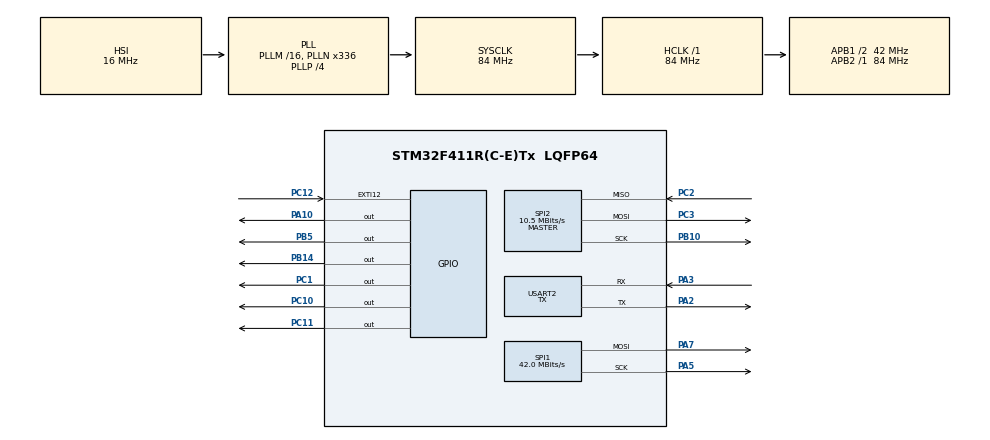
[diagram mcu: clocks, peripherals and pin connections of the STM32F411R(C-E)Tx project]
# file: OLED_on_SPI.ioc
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FREERTOS.Tasks01=defaultTask,8,128,StartDefaultTask,Default,NULL,Dynamic,NULL,NULL
FREERTOS.configCHECK_FOR_STACK_OVERFLOW=1
FREERTOS.configENABLE_FPU=1
FREERTOS.configTIMER_TASK_PRIORITY=12
FREERTOS.configTOTAL_HEAP_SIZE=30360
FREERTOS.configUSE_NEWLIB_REENTRANT=1
FREERTOS.configUSE_OS2_TIMER=0
MBEDTLS.MBEDTLS_DEBUG_C=1
MBEDTLS.MBEDTLS_HAVE_TIME=0
MBEDTLS.MBEDTLS_KEY_EXCHANGE_ECDHE_ECDSA_ENABLED=0
MBEDTLS.MBEDTLS_KEY_EXCHANGE_ECDHE_RSA_ENABLED=1
MBEDTLS.MBEDTLS_KEY_EXCHANGE_ECDH_RSA_ENABLED=1
MBEDTLS.MBEDTLS_KEY_EXCHANGE_PSK_ENABLED=0
MBEDTLS.MBEDTLS_KEY_EXCHANGE_RSA_ENABLED=1
MBEDTLS.MBEDTLS_MPI_MAX_SIZE=512
MBEDTLS.MBEDTLS_PKCS1_V15=1
MBEDTLS.MBEDTLS_RSA_C=1
MBEDTLS.MBEDTLS_SHA512_C=0
MBEDTLS.MBEDTLS_SSL_CIPHERSUITES=MBEDTLS_TLS_ECDHE_RSA_WITH_AES_128_GCM_SHA256
MBEDTLS.MBEDTLS_SSL_CLI_C=1
MBEDTLS.MBEDTLS_SSL_MAX_FRAGMENT_LENGTH=1
MBEDTLS.MBEDTLS_SSL_SERVER_NAME_INDICATION=1
Mcu.Family=STM32F4
Mcu.Name=STM32F411R(C-E)Tx
Mcu.Package=LQFP64
NVIC.EXTI15_10_IRQn=true\:5\:0\:false\:false\:true\:true\:true\:true\:true
NVIC.PriorityGroup=NVIC_PRIORITYGROUP_4
NVIC.TIM1_UP_TIM10_IRQn=true\:15\:0\:false\:false\:true\:false\:false\:true\:true
NVIC.TimeBase=TIM1_UP_TIM10_IRQn
NVIC.TimeBaseIP=TIM1
PA10.PinState=GPIO_PIN_SET
PA10.Signal=GPIO_Output
PA13.GPIO_Label=TMS
PA13.Signal=SYS_JTMS-SWDIO
PA14.GPIO_Label=TCK
PA14.Signal=SYS_JTCK-SWCLK
PA2.Mode=Asynchronous
PA2.Signal=USART2_TX
PA3.Mode=Asynchronous
PA3.Signal=USART2_RX
PA5.GPIO_Speed=GPIO_SPEED_FREQ_HIGH
PA5.Mode=TX_Only_Simplex_Unidirect_Master
PA5.Signal=SPI1_SCK
PA7.GPIO_Speed=GPIO_SPEED_FREQ_HIGH
PA7.Mode=TX_Only_Simplex_Unidirect_Master
PA7.Signal=SPI1_MOSI
PB10.Mode=Full_Duplex_Master
PB10.Signal=SPI2_SCK
PB14.PinState=GPIO_PIN_SET
PB14.Signal=GPIO_Output
PB3.GPIO_Label=SWO
PB3.Signal=SYS_JTDO-SWO
PB5.PinState=GPIO_PIN_SET
PB5.Signal=GPIO_Output
PC1.PinState=GPIO_PIN_SET
PC1.Signal=GPIO_Output
PC10.GPIO_Speed=GPIO_SPEED_FREQ_VERY_HIGH
PC10.PinState=GPIO_PIN_SET
PC10.Signal=GPIO_Output
PC11.PinState=GPIO_PIN_SET
PC11.Signal=GPIO_Output
PC12.GPIO_ModeDefaultEXTI=GPIO_MODE_IT_FALLING
PC12.GPIO_PuPd=GPIO_PULLUP
PC12.Signal=GPXTI12
PC14-OSC32_IN.Signal=RCC_OSC32_IN
PC15-OSC32_OUT.Signal=RCC_OSC32_OUT
PC2.Mode=Full_Duplex_Master
PC2.Signal=SPI2_MISO
PC3.Mode=Full_Duplex_Master
PC3.Signal=SPI2_MOSI
PH0\ -\ OSC_IN.Signal=RCC_OSC_IN
PH1\ -\ OSC_OUT.Signal=RCC_OSC_OUT
ProjectManager.HeapSize=0x200
ProjectManager.StackSize=0x400
ProjectManager.TargetToolchain=STM32CubeIDE
RCC.48MHZClocksFreq_Value=84000000
RCC.AHBFreq_Value=84000000
RCC.APB1CLKDivider=RCC_HCLK_DIV2
RCC.APB1Freq_Value=42000000
RCC.APB1TimFreq_Value=84000000
RCC.APB2Freq_Value=84000000
RCC.APB2TimFreq_Value=84000000
RCC.CortexFreq_Value=84000000
RCC.FLatency-AdvancedSettings=FLASH_LATENCY_2
RCC.HCLKFreq_Value=84000000
RCC.HSE_VALUE=8000000
RCC.HSI_VALUE=16000000
RCC.LSE_VALUE=32768
RCC.PLLN=336
RCC.PLLP=RCC_PLLP_DIV4
RCC.SYSCLKFreq_VALUE=84000000
RCC.SYSCLKSource=RCC_SYSCLKSOURCE_PLLCLK
RCC.VCOOutputFreq_Value=336000000
SPI1.CalculateBaudRate=42.0 MBits/s
SPI1.Direction=SPI_DIRECTION_2LINES
SPI1.Mode=SPI_MODE_MASTER
SPI1.VirtualType=VM_MASTER
SPI2.BaudRatePrescaler=SPI_BAUDRATEPRESCALER_4
SPI2.CalculateBaudRate=10.5 MBits/s
SPI2.Direction=SPI_DIRECTION_2LINES
SPI2.Mode=SPI_MODE_MASTER
SPI2.VirtualType=VM_MASTER
USART2.Mode=MODE_TX
USART2.VirtualMode=VM_ASYNC
VP_FREERTOS_VS_CMSIS_V2.Mode=CMSIS_V2
VP_MBEDTLS_VS_MBEDTLS.Mode=Enabled
VP_SYS_VS_tim1.Mode=TIM1
board=NUCLEO-F411RE
wolfSSL.I-CUBE-wolfSSL.5.9.2.WOLF_CONF_RTOS=2

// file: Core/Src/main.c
/* USER CODE BEGIN Header */
/**
  ******************************************************************************
  * @file           : main.c
  * @brief          : Main program body
  ******************************************************************************
  * @attention
  *
  * Copyright (c) 2026 STMicroelectronics.
  * All rights reserved.
  *
  * This software is licensed under terms that can be found in the LICENSE file
  * in the root directory of this software component.
  * If no LICENSE file comes with this software, it is provided AS-IS.
  *
  ******************************************************************************
  */
/* USER CODE END Header */
#include "main.h"
#include "cmsis_os.h"
#include "mbedtls.h"

/* USER CODE BEGIN Includes */

#include <string.h>
#include <stdio.h>

//#include "UART.h"
/* USER CODE END Includes */

SPI_HandleTypeDef hspi1;
SPI_HandleTypeDef hspi2;

UART_HandleTypeDef huart2;

/* Definitions for defaultTask */
osThreadId_t defaultTaskHandle;
const osThreadAttr_t defaultTask_attributes = {
  .name = "defaultTask",
  .stack_size = 128 * 4,
  .priority = (osPriority_t) osPriorityLow,
};

void SystemClock_Config(void);
static void MX_GPIO_Init(void);
static void MX_SPI1_Init(void);
static void MX_SPI2_Init(void);
static void MX_USART2_UART_Init(void);
void StartDefaultTask(void *argument);

/* USER CODE BEGIN PFP */
extern void main_thread_entry(void);

void DWT_Init(void);
/* USER CODE END PFP */

int main(void)
{

  /* MCU Configuration--------------------------------------------------------*/

  /* Reset of all peripherals, Initializes the Flash interface and the Systick. */
  HAL_Init();

  /* Configure the system clock */
  SystemClock_Config();

  /* Initialize all configured peripherals */
  MX_GPIO_Init();
  MX_SPI1_Init();
  MX_SPI2_Init();
  MX_USART2_UART_Init();
  /* Call PreOsInit function */
  MX_MBEDTLS_Init();
  /* USER CODE BEGIN 2 */

  	HAL_Delay(50);

  	DWT_Init();
  	//HAL_UART_Receive_IT(&huart6, &UART6_RX_Buffer[UART6_RX_Index], 1);

  	//ESP8266_test_sequence_init();

	//	ENC28J60_Init();

		//ENC28J60GPIOInit();

  /* USER CODE END 2 */

  /* Init scheduler */
  osKernelInitialize();

  /* Create the thread(s) */
  /* creation of defaultTask */
  defaultTaskHandle = osThreadNew(StartDefaultTask, NULL, &defaultTask_attributes);

  /* USER CODE BEGIN RTOS_THREADS */
  /* add threads, ... */
  	  main_thread_entry();
  /* USER CODE END RTOS_THREADS */

  /* Start scheduler */
  osKernelStart();

  /* We should never get here as control is now taken by the scheduler */

  /* Infinite loop */
  /* USER CODE BEGIN WHILE */
  while (1)   //RTOS should not reach here
  {
//		 ssd1306_Fill(White);
//	  		  ssd1306_UpdateScreen();
//
//	  		  HAL_Delay(500);
//	  		ssd1306_Fill(Black);
//	  	  ssd1306_UpdateScreen();
//	  	HAL_Delay(500);
//	  		  ssd1306_DrawPixel(35,20,White);
//	  		  ssd1306_UpdateScreen();
//	  		 HAL_Delay(500);
//	  		  ssd1306_FillRectangle(12,90,50,60,White);
//	  		  ssd1306_UpdateScreen();
//	  		HAL_Delay(500);
	  		//ssd1306_Fill(Black);
	  			  	 // ssd1306_UpdateScreen();
	  			 // HAL_Delay(500);
	  		//ssd1306_TestFonts2();
//	 HAL_GPIO_WritePin(GPIOC, GPIO_PIN_1, GPIO_PIN_RESET);
//	 HAL_Delay(500);
//	  HAL_GPIO_WritePin(GPIOC, GPIO_PIN_1, GPIO_PIN_SET);
//	 HAL_Delay(500);
	  	//  DHT22_GetTemp_Humidity(&temp,&humid);
				  //ethernetif_input(&gnetif);
				  // poll ENC28J60 for packets
				        //  sys_check_timeouts();
				//  ReadBufferMem(data_lan_rx, 50);
				// ESP8266_test_sequence_transmit();
				//HAL_Delay(500);

    /* USER CODE END WHILE */

  }
}

void SystemClock_Config(void)
{
  RCC_OscInitTypeDef RCC_OscInitStruct = {0};
  RCC_ClkInitTypeDef RCC_ClkInitStruct = {0};

  /** Configure the main internal regulator output voltage
  */
  __HAL_RCC_PWR_CLK_ENABLE();
  __HAL_PWR_VOLTAGESCALING_CONFIG(PWR_REGULATOR_VOLTAGE_SCALE1);

  /** Initializes the RCC Oscillators according to the specified parameters
  * in the RCC_OscInitTypeDef structure.
  */
  RCC_OscInitStruct.OscillatorType = RCC_OSCILLATORTYPE_HSI;
  RCC_OscInitStruct.HSIState = RCC_HSI_ON;
  RCC_OscInitStruct.HSICalibrationValue = RCC_HSICALIBRATION_DEFAULT;
  RCC_OscInitStruct.PLL.PLLState = RCC_PLL_ON;
  RCC_OscInitStruct.PLL.PLLSource = RCC_PLLSOURCE_HSI;
  RCC_OscInitStruct.PLL.PLLM = 16;
  RCC_OscInitStruct.PLL.PLLN = 336;
  RCC_OscInitStruct.PLL.PLLP = RCC_PLLP_DIV4;
  RCC_OscInitStruct.PLL.PLLQ = 4;
  if (HAL_RCC_OscConfig(&RCC_OscInitStruct) != HAL_OK)
  {
    Error_Handler();
  }

  /** Initializes the CPU, AHB and APB buses clocks
  */
  RCC_ClkInitStruct.ClockType = RCC_CLOCKTYPE_HCLK|RCC_CLOCKTYPE_SYSCLK
                              |RCC_CLOCKTYPE_PCLK1|RCC_CLOCKTYPE_PCLK2;
  RCC_ClkInitStruct.SYSCLKSource = RCC_SYSCLKSOURCE_PLLCLK;
  RCC_ClkInitStruct.AHBCLKDivider = RCC_SYSCLK_DIV1;
  RCC_ClkInitStruct.APB1CLKDivider = RCC_HCLK_DIV2;
  RCC_ClkInitStruct.APB2CLKDivider = RCC_HCLK_DIV1;

  if (HAL_RCC_ClockConfig(&RCC_ClkInitStruct, FLASH_LATENCY_2) != HAL_OK)
  {
    Error_Handler();
  }
}

static void MX_SPI1_Init(void)
{

  /* SPI1 parameter configuration*/
  hspi1.Instance = SPI1;
  hspi1.Init.Mode = SPI_MODE_MASTER;
  hspi1.Init.Direction = SPI_DIRECTION_2LINES;
  hspi1.Init.DataSize = SPI_DATASIZE_8BIT;
  hspi1.Init.CLKPolarity = SPI_POLARITY_LOW;
  hspi1.Init.CLKPhase = SPI_PHASE_1EDGE;
  hspi1.Init.NSS = SPI_NSS_SOFT;
  hspi1.Init.BaudRatePrescaler = SPI_BAUDRATEPRESCALER_2;
  hspi1.Init.FirstBit = SPI_FIRSTBIT_MSB;
  hspi1.Init.TIMode = SPI_TIMODE_DISABLE;
  hspi1.Init.CRCCalculation = SPI_CRCCALCULATION_DISABLE;
  hspi1.Init.CRCPolynomial = 10;
  if (HAL_SPI_Init(&hspi1) != HAL_OK)
  {
    Error_Handler();
  }

}

static void MX_SPI2_Init(void)
{

  /* SPI2 parameter configuration*/
  hspi2.Instance = SPI2;
  hspi2.Init.Mode = SPI_MODE_MASTER;
  hspi2.Init.Direction = SPI_DIRECTION_2LINES;
  hspi2.Init.DataSize = SPI_DATASIZE_8BIT;
  hspi2.Init.CLKPolarity = SPI_POLARITY_LOW;
  hspi2.Init.CLKPhase = SPI_PHASE_1EDGE;
  hspi2.Init.NSS = SPI_NSS_SOFT;
  hspi2.Init.BaudRatePrescaler = SPI_BAUDRATEPRESCALER_4;
  hspi2.Init.FirstBit = SPI_FIRSTBIT_MSB;
  hspi2.Init.TIMode = SPI_TIMODE_DISABLE;
  hspi2.Init.CRCCalculation = SPI_CRCCALCULATION_DISABLE;
  hspi2.Init.CRCPolynomial = 10;
  if (HAL_SPI_Init(&hspi2) != HAL_OK)
  {
    Error_Handler();
  }

}

static void MX_USART2_UART_Init(void)
{

  huart2.Instance = USART2;
  huart2.Init.BaudRate = 115200;
  huart2.Init.WordLength = UART_WORDLENGTH_8B;
  huart2.Init.StopBits = UART_STOPBITS_1;
  huart2.Init.Parity = UART_PARITY_NONE;
  huart2.Init.Mode = UART_MODE_TX;
  huart2.Init.HwFlowCtl = UART_HWCONTROL_NONE;
  huart2.Init.OverSampling = UART_OVERSAMPLING_16;
  if (HAL_UART_Init(&huart2) != HAL_OK)
  {
    Error_Handler();
  }

}

static void MX_GPIO_Init(void)
{
  GPIO_InitTypeDef GPIO_InitStruct = {0};

  /* GPIO Ports Clock Enable */
  __HAL_RCC_GPIOC_CLK_ENABLE();
  __HAL_RCC_GPIOH_CLK_ENABLE();
  __HAL_RCC_GPIOA_CLK_ENABLE();
  __HAL_RCC_GPIOB_CLK_ENABLE();

  /*Configure GPIO pin Output Level */
  HAL_GPIO_WritePin(GPIOC, GPIO_PIN_1|GPIO_PIN_10|GPIO_PIN_11, GPIO_PIN_SET);

  /*Configure GPIO pin Output Level */
  HAL_GPIO_WritePin(GPIOB, GPIO_PIN_14|GPIO_PIN_5, GPIO_PIN_SET);

  /*Configure GPIO pin Output Level */
  HAL_GPIO_WritePin(GPIOA, GPIO_PIN_10, GPIO_PIN_SET);

  /*Configure GPIO pins : PC1 PC11 */
  GPIO_InitStruct.Pin = GPIO_PIN_1|GPIO_PIN_11;
  GPIO_InitStruct.Mode = GPIO_MODE_OUTPUT_PP;
  GPIO_InitStruct.Pull = GPIO_NOPULL;
  GPIO_InitStruct.Speed = GPIO_SPEED_FREQ_LOW;
  HAL_GPIO_Init(GPIOC, &GPIO_InitStruct);

  /*Configure GPIO pins : PB14 PB5 */
  GPIO_InitStruct.Pin = GPIO_PIN_14|GPIO_PIN_5;
  GPIO_InitStruct.Mode = GPIO_MODE_OUTPUT_PP;
  GPIO_InitStruct.Pull = GPIO_NOPULL;
  GPIO_InitStruct.Speed = GPIO_SPEED_FREQ_LOW;
  HAL_GPIO_Init(GPIOB, &GPIO_InitStruct);

  /*Configure GPIO pin : PA10 */
  GPIO_InitStruct.Pin = GPIO_PIN_10;
  GPIO_InitStruct.Mode = GPIO_MODE_OUTPUT_PP;
  GPIO_InitStruct.Pull = GPIO_NOPULL;
  GPIO_InitStruct.Speed = GPIO_SPEED_FREQ_LOW;
  HAL_GPIO_Init(GPIOA, &GPIO_InitStruct);

  /*Configure GPIO pin : PC10 */
  GPIO_InitStruct.Pin = GPIO_PIN_10;
  GPIO_InitStruct.Mode = GPIO_MODE_OUTPUT_PP;
  GPIO_InitStruct.Pull = GPIO_NOPULL;
  GPIO_InitStruct.Speed = GPIO_SPEED_FREQ_VERY_HIGH;
  HAL_GPIO_Init(GPIOC, &GPIO_InitStruct);

  /*Configure GPIO pin : PC12 */
  GPIO_InitStruct.Pin = GPIO_PIN_12;
  GPIO_InitStruct.Mode = GPIO_MODE_IT_FALLING;
  GPIO_InitStruct.Pull = GPIO_PULLUP;
  HAL_GPIO_Init(GPIOC, &GPIO_InitStruct);

  /* EXTI interrupt init*/
  HAL_NVIC_SetPriority(EXTI15_10_IRQn, 5, 0);
  HAL_NVIC_EnableIRQ(EXTI15_10_IRQn);

}

/* USER CODE BEGIN 4 */
void DWT_Init(void)
{
    CoreDebug->DEMCR |= CoreDebug_DEMCR_TRCENA_Msk;
    DWT->CYCCNT = 0;
    DWT->CTRL |= DWT_CTRL_CYCCNTENA_Msk;
}
void hSPI2_init(){
MX_SPI2_Init();
}
/* USER CODE END 4 */

void StartDefaultTask(void *argument)
{
  for(;;)
  {
    osDelay(1);
  }
}

void HAL_TIM_PeriodElapsedCallback(TIM_HandleTypeDef *htim)
{
  if (htim->Instance == TIM1)
  {
    HAL_IncTick();
  }
}

void Error_Handler(void)
{
  __disable_irq();
  while (1)
  {
  }
}

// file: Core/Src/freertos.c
/* USER CODE BEGIN Header */
/**
  ******************************************************************************
  * File Name          : freertos.c
  * Description        : Code for freertos applications
  ******************************************************************************
  * @attention
  *
  * Copyright (c) 2026 STMicroelectronics.
  * All rights reserved.
  *
  * This software is licensed under terms that can be found in the LICENSE file
  * in the root directory of this software component.
  * If no LICENSE file comes with this software, it is provided AS-IS.
  *
  ******************************************************************************
  */
/* USER CODE END Header */

#include "FreeRTOS.h"
#include "task.h"
#include "main.h"

/* Hook prototypes */
void vApplicationStackOverflowHook(xTaskHandle xTask, signed char *pcTaskName);

/* USER CODE BEGIN 4 */
void vApplicationStackOverflowHook(xTaskHandle xTask, signed char *pcTaskName)
{
   /* Run time stack overflow checking is performed if
   configCHECK_FOR_STACK_OVERFLOW is defined to 1 or 2. This hook function is
   called if a stack overflow is detected. */
	printf("FATAL: Stack Overflow in task: %s\r\n", pcTaskName);
	    while (1) {
	        // Trap it here. Toggle an LED rapidly so you see it physically.
	    }
}
/* USER CODE END 4 */
